AUTOSAR XML (schema 00045)
package /VdyAdapter
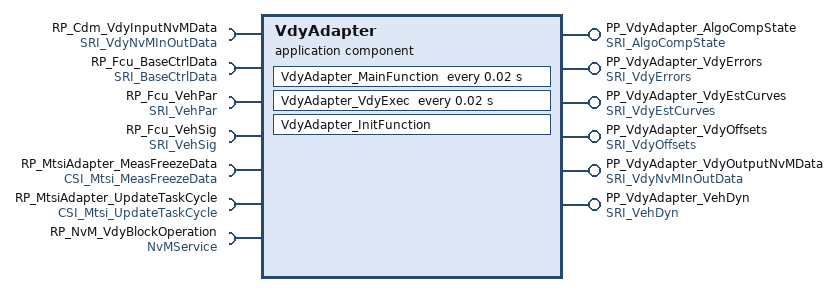
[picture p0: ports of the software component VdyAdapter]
  application sw component type VdyAdapter  # Vehicle Dynamic Yaw
    6 x provide port:
      PP_VdyAdapter_AlgoCompState: provided-interface=SRI_AlgoCompState
      PP_VdyAdapter_VdyErrors: provided-interface=SRI_VdyErrors
      PP_VdyAdapter_VdyEstCurves: provided-interface=SRI_VdyEstCurves
      PP_VdyAdapter_VdyOffsets: provided-interface=SRI_VdyOffsets
      PP_VdyAdapter_VdyOutputNvMData: provided-interface=SRI_VdyNvMInOutData
      PP_VdyAdapter_VehDyn: provided-interface=SRI_VehDyn
    7 x require port:
      RP_Cdm_VdyInputNvMData: required-interface=SRI_VdyNvMInOutData
      RP_Fcu_BaseCtrlData: required-interface=SRI_BaseCtrlData
      RP_Fcu_VehPar: required-interface=SRI_VehPar
      RP_Fcu_VehSig: required-interface=SRI_VehSig
      RP_MtsiAdapter_MeasFreezeData: required-interface=CSI_Mtsi_MeasFreezeData
      RP_MtsiAdapter_UpdateTaskCycle: required-interface=CSI_Mtsi_UpdateTaskCycle
      RP_NvM_VdyBlockOperation: required-interface=NvMService
    behavior VdyAdapter_IB: handle-termination-and-restart=NO-SUPPORT
      init event InitEvent_VdyAdapter_InitFunction: start-on-event=VdyAdapter_InitFunction
      timing event TimingEvent_VdyAdapter_MainFunction: start-on-event=VdyAdapter_MainFunction, period=0.02
      timing event TimingEvent_VdyAdapter_VdyExec: start-on-event=VdyAdapter_VdyExec, period=0.02
      runnable VdyAdapter_InitFunction
        data-receive-point-by-arguments:
          4 x access:
            drparg_BaseCtrlData: accessed-variable=RP_Fcu_BaseCtrlData.BaseCtrlData
            drparg_VdyNvMInOutData: accessed-variable=RP_Cdm_VdyInputNvMData.VdyNvMInOutData
            drparg_VehPar: accessed-variable=RP_Fcu_VehPar.VehPar
            drparg_VehSig: accessed-variable=RP_Fcu_VehSig.VehSig
        data-send-points:
          6 x access:
            dsp_AlgoCompState: accessed-variable=PP_VdyAdapter_AlgoCompState.AlgoCompState
            dsp_VdyErrors: accessed-variable=PP_VdyAdapter_VdyErrors.VdyErrors
            dsp_VdyEstCurves: accessed-variable=PP_VdyAdapter_VdyEstCurves.VdyEstCurves
            dsp_VdyNvMInOutData: accessed-variable=PP_VdyAdapter_VdyOutputNvMData.VdyNvMInOutData
            dsp_VdyOffsets: accessed-variable=PP_VdyAdapter_VdyOffsets.VdyOffsets
            dsp_VehDyn: accessed-variable=PP_VdyAdapter_VehDyn.VehDyn
      runnable VdyAdapter_MainFunction
        data-receive-point-by-arguments:
          4 x access:
            drparg_BaseCtrlData: accessed-variable=RP_Fcu_BaseCtrlData.BaseCtrlData
            drparg_VdyNvMInOutData: accessed-variable=RP_Cdm_VdyInputNvMData.VdyNvMInOutData
            drparg_VehPar: accessed-variable=RP_Fcu_VehPar.VehPar
            drparg_VehSig: accessed-variable=RP_Fcu_VehSig.VehSig
        data-send-points:
          6 x access:
            dsp_AlgoCompState: accessed-variable=PP_VdyAdapter_AlgoCompState.AlgoCompState
            dsp_VdyErrors: accessed-variable=PP_VdyAdapter_VdyErrors.VdyErrors
            dsp_VdyEstCurves: accessed-variable=PP_VdyAdapter_VdyEstCurves.VdyEstCurves
            dsp_VdyNvMInOutData: accessed-variable=PP_VdyAdapter_VdyOutputNvMData.VdyNvMInOutData
            dsp_VdyOffsets: accessed-variable=PP_VdyAdapter_VdyOffsets.VdyOffsets
            dsp_VehDyn: accessed-variable=PP_VdyAdapter_VehDyn.VehDyn
        4 x sync call, all with timeout=0.0:
          scp_GetErrorStatus: operation=RP_NvM_VdyBlockOperation.GetErrorStatus
          scp_ReadBlock: operation=RP_NvM_VdyBlockOperation.ReadBlock
          scp_SetRamBlockStatus: operation=RP_NvM_VdyBlockOperation.SetRamBlockStatus
          scp_WriteBlock: operation=RP_NvM_VdyBlockOperation.WriteBlock
      runnable VdyAdapter_VdyExec
        data-receive-point-by-arguments:
          4 x access:
            drparg_BaseCtrlData: accessed-variable=RP_Fcu_BaseCtrlData.BaseCtrlData
            drparg_VdyNvMInOutData: accessed-variable=RP_Cdm_VdyInputNvMData.VdyNvMInOutData
            drparg_VehPar: accessed-variable=RP_Fcu_VehPar.VehPar
            drparg_VehSig: accessed-variable=RP_Fcu_VehSig.VehSig
        data-send-points:
          6 x access:
            dsp_AlgoCompState: accessed-variable=PP_VdyAdapter_AlgoCompState.AlgoCompState
            dsp_VdyErrors: accessed-variable=PP_VdyAdapter_VdyErrors.VdyErrors
            dsp_VdyEstCurves: accessed-variable=PP_VdyAdapter_VdyEstCurves.VdyEstCurves
            dsp_VdyNvMInOutData: accessed-variable=PP_VdyAdapter_VdyOutputNvMData.VdyNvMInOutData
            dsp_VdyOffsets: accessed-variable=PP_VdyAdapter_VdyOffsets.VdyOffsets
            dsp_VehDyn: accessed-variable=PP_VdyAdapter_VehDyn.VehDyn
        sync call scp_MeasFreezeData: operation=RP_MtsiAdapter_MeasFreezeData.MeasFreezeData, timeout=0.0
        sync call scp_UpdateTaskCycle: operation=RP_MtsiAdapter_UpdateTaskCycle.UpdateTaskCycle, timeout=0.0
  swc implementation VdyAdapterImpl: programming-language=C, sw-version=1.0.0, vendor-id=0, behavior=VdyAdapter_IB
    code-descriptors:
      code CodeGen: artifact-descriptors=[{short-label=SWSRC, category=SWSRC}, {short-label=SWHDR, category=SWHDR}]
    resource consumption Resource
      memory section CODE: sw-addrmethod=CODE
      memory section VAR_UNSPECIFIED: sw-addrmethod=VAR
